VERSION "HIPBNYYYYYYYYYYYYYYYYYYYYYYYYYYYYYYYYYYYYY/4/%%%/4/'%**4YYY///"

BO_ 1027 Detection_PCB: 8 DAQ
 SG_ DetectionSignal : 0|8@1- (1,0) [0|1] "On/Off" VCU

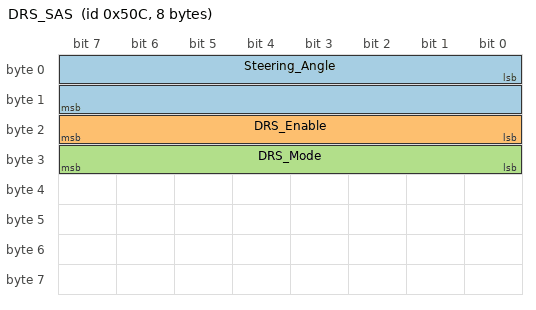
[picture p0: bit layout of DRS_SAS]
BO_ 1292 DRS_SAS: 8 DAQ
 SG_ Steering_Angle : 0|16@1- (1,0) [-100|100] "Degrees" VCU
 SG_ DRS_Enable : 16|8@1+ (1,0) [0|1] "Enable" VCU
 SG_ DRS_Mode : 24|8@1+ (1,0) [0|3] "Selection" VCU
